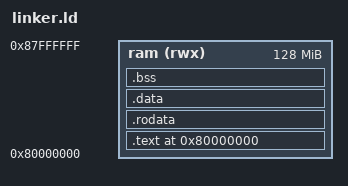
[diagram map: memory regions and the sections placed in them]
ENTRY(_start)

MEMORY
{
    ram (rwx) : ORIGIN = 0x80000000, LENGTH = 128M
}

SECTIONS
{
    . = 0x80000000;

    .text : {
        KEEP(*(.text.init))
        *(.text .text.*)
    } > ram

    .rodata : {
        *(.rodata .rodata.*)
    } > ram

    .data : {
        *(.data .data.*)
    } > ram

    .bss : {
        *(.bss .bss.*)
        *(COMMON)
    } > ram

    /DISCARD/ : {
        *(.eh_frame)
        *(.comment)
    }
}
